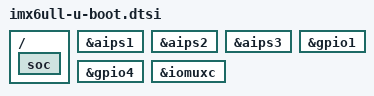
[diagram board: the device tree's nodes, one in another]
// SPDX-License-Identifier: GPL-2.0+
/*
 * Copyright (C) 2019 Parthiban Nallathambi <parthitce@gmail.com>
 */

/ {
	soc {
		bootph-pre-ram;
	};
};

&aips1 {
	bootph-pre-ram;
};

&aips2 {
	bootph-pre-ram;
};

&aips3 {
	bootph-pre-ram;
};

&gpio1 {
	bootph-pre-ram;
};

&gpio4 {
	bootph-pre-ram;
};

&iomuxc {
	bootph-pre-ram;
};
